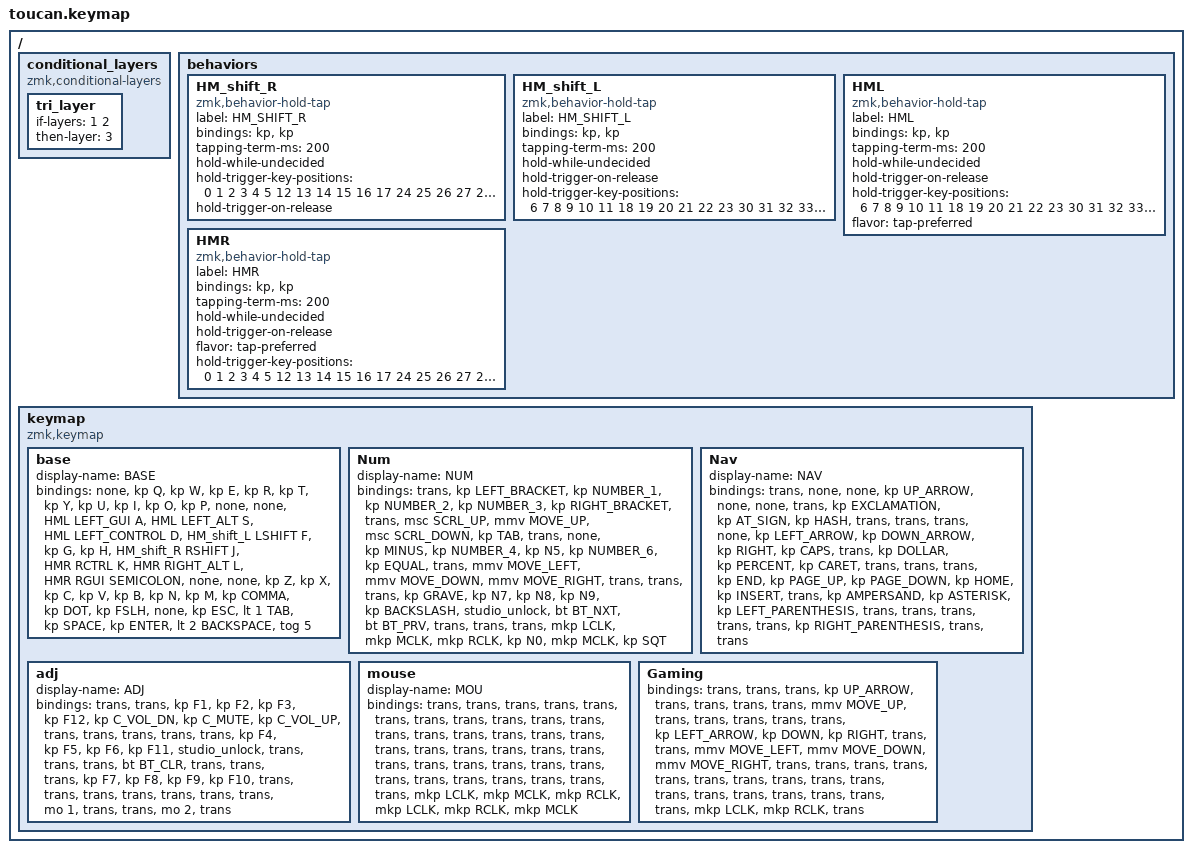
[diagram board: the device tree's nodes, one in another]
#include <behaviors.dtsi>
#include <dt-bindings/zmk/bt.h>
#include <dt-bindings/zmk/keys.h>
#include <dt-bindings/zmk/pointing.h>

#define BASE 0
#define NAV  1
#define SYM  2
#define ADJ  3

/ {
    conditional_layers {
        compatible = "zmk,conditional-layers";

        tri_layer {
            if-layers = <1 2>;
            then-layer = <3>;
        };
    };

    behaviors {
        HM_shift_R: HM_shift_R {
            compatible = "zmk,behavior-hold-tap";
            label = "HM_SHIFT_R";
            bindings = <&kp>, <&kp>;

            #binding-cells = <2>;
            tapping-term-ms = <200>;
            hold-while-undecided;
            hold-trigger-key-positions = <0 1 2 3 4 5 12 13 14 15 16 17 24 25 26 27 28 29 36 37 38>;
            hold-trigger-on-release;
        };

        HM_shift_L: HM_shift_L {
            compatible = "zmk,behavior-hold-tap";
            label = "HM_SHIFT_L";
            bindings = <&kp>, <&kp>;

            #binding-cells = <2>;
            tapping-term-ms = <200>;
            hold-while-undecided;
            hold-trigger-on-release;
            hold-trigger-key-positions = <6 7 8 9 10 11 18 19 20 21 22 23 30 31 32 33 34 35 39 40 41>;
        };

        HML: HML {
            compatible = "zmk,behavior-hold-tap";
            label = "HML";
            bindings = <&kp>, <&kp>;

            #binding-cells = <2>;
            tapping-term-ms = <200>;
            hold-while-undecided;
            hold-trigger-on-release;
            hold-trigger-key-positions = <6 7 8 9 10 11 18 19 20 21 22 23 30 31 32 33 34 35 39 40 41>;
            flavor = "tap-preferred";
        };

        HMR: HMR {
            compatible = "zmk,behavior-hold-tap";
            label = "HMR";
            bindings = <&kp>, <&kp>;

            #binding-cells = <2>;
            tapping-term-ms = <200>;
            hold-while-undecided;
            hold-trigger-on-release;
            flavor = "tap-preferred";
            hold-trigger-key-positions = <0 1 2 3 4 5 12 13 14 15 16 17 24 25 26 27 28 29 36 37 38>;
        };
    };

    keymap {
        compatible = "zmk,keymap";

        base {
            display-name = "BASE";
            bindings = <
&none  &kp Q  &kp W  &kp E  &kp R  &kp T  &kp Y  &kp U  &kp I  &kp O  &kp P  &none  &none  &HML LEFT_GUI A  &HML LEFT_ALT S  &HML LEFT_CONTROL D  &HM_shift_L LSHIFT F  &kp G  &kp H  &HM_shift_R RSHIFT J  &HMR RCTRL K  &HMR RIGHT_ALT L  &HMR RGUI SEMICOLON  &none  &none  &kp Z  &kp X  &kp C  &kp V  &kp B  &kp N  &kp M  &kp COMMA  &kp DOT  &kp FSLH  &none  &kp ESC  &lt 1 TAB  &kp SPACE  &kp ENTER  &lt 2 BACKSPACE  &tog 5
            >;
        };

        Num {
            display-name = "NUM";
            bindings = <
&trans  &kp LEFT_BRACKET  &kp NUMBER_1  &kp NUMBER_2  &kp NUMBER_3  &kp RIGHT_BRACKET  &trans  &msc SCRL_UP  &mmv MOVE_UP  &msc SCRL_DOWN  &kp TAB  &trans  &none  &kp MINUS  &kp NUMBER_4  &kp N5  &kp NUMBER_6  &kp EQUAL  &trans  &mmv MOVE_LEFT  &mmv MOVE_DOWN  &mmv MOVE_RIGHT  &trans  &trans  &trans  &kp GRAVE  &kp N7  &kp N8  &kp N9  &kp BACKSLASH  &studio_unlock  &bt BT_NXT  &bt BT_PRV  &trans  &trans  &trans  &mkp LCLK  &mkp MCLK  &mkp RCLK  &kp N0  &mkp MCLK  &kp SQT
            >;
        };

        Nav {
            display-name = "NAV";
            bindings = <
&trans  &none  &none  &kp UP_ARROW  &none  &none  &trans  &kp EXCLAMATION  &kp AT_SIGN  &kp HASH  &trans  &trans  &trans  &none  &kp LEFT_ARROW  &kp DOWN_ARROW  &kp RIGHT  &kp CAPS  &trans  &kp DOLLAR  &kp PERCENT  &kp CARET  &trans  &trans  &trans  &kp END  &kp PAGE_UP  &kp PAGE_DOWN  &kp HOME  &kp INSERT  &trans  &kp AMPERSAND  &kp ASTERISK  &kp LEFT_PARENTHESIS  &trans  &trans  &trans  &trans  &trans  &kp RIGHT_PARENTHESIS  &trans  &trans
            >;
        };

        adj {
            display-name = "ADJ";
            bindings = <
&trans  &trans  &kp F1  &kp F2  &kp F3  &kp F12  &kp C_VOL_DN  &kp C_MUTE  &kp C_VOL_UP  &trans  &trans  &trans  &trans  &trans  &kp F4  &kp F5  &kp F6  &kp F11  &studio_unlock  &trans  &trans  &trans  &bt BT_CLR  &trans  &trans  &trans  &kp F7  &kp F8  &kp F9  &kp F10  &trans  &trans  &trans  &trans  &trans  &trans  &trans  &mo 1  &trans  &trans  &mo 2  &trans
            >;
        };

        mouse {
            display-name = "MOU";
            bindings = <
&trans  &trans  &trans  &trans  &trans  &trans  &trans  &trans  &trans  &trans  &trans  &trans  &trans  &trans  &trans  &trans  &trans  &trans  &trans  &trans  &trans  &trans  &trans  &trans  &trans  &trans  &trans  &trans  &trans  &trans  &trans  &trans  &trans  &trans  &trans  &trans  &mkp LCLK  &mkp MCLK  &mkp RCLK  &mkp LCLK  &mkp RCLK  &mkp MCLK
            >;
        };

        Gaming {
            bindings = <
&trans  &trans  &trans  &kp UP_ARROW  &trans  &trans  &trans  &trans  &mmv MOVE_UP  &trans  &trans  &trans  &trans  &trans  &kp LEFT_ARROW  &kp DOWN  &kp RIGHT  &trans  &trans  &mmv MOVE_LEFT  &mmv MOVE_DOWN  &mmv MOVE_RIGHT  &trans  &trans  &trans  &trans  &trans  &trans  &trans  &trans  &trans  &trans  &trans  &trans  &trans  &trans  &trans  &trans  &trans  &mkp LCLK  &mkp RCLK  &trans
            >;
        };
    };
};
